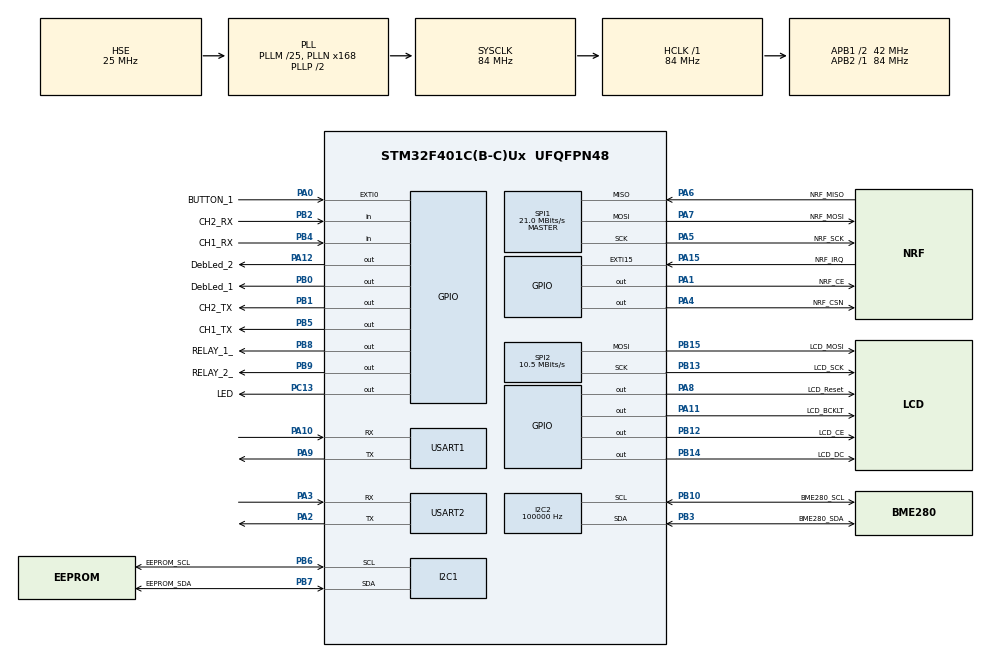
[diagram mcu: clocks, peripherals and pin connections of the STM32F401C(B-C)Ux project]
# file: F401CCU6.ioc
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Dma.Request0=SPI2_TX
Dma.SPI2_TX.0.Direction=DMA_MEMORY_TO_PERIPH
Dma.SPI2_TX.0.FIFOMode=DMA_FIFOMODE_DISABLE
Dma.SPI2_TX.0.Instance=DMA1_Stream4
Dma.SPI2_TX.0.MemDataAlignment=DMA_MDATAALIGN_BYTE
Dma.SPI2_TX.0.MemInc=DMA_MINC_ENABLE
Dma.SPI2_TX.0.Mode=DMA_NORMAL
Dma.SPI2_TX.0.PeriphDataAlignment=DMA_PDATAALIGN_BYTE
Dma.SPI2_TX.0.PeriphInc=DMA_PINC_DISABLE
Dma.SPI2_TX.0.Priority=DMA_PRIORITY_LOW
FREERTOS.CountingSemaphores01=localMsmntSem,5,Static,localMsmntSemControlBlock;txPrintSem,5,Static,nRF_txPrintSemControlBlock;tableSensDataSem,5,Static,tableSensDataSemControlBlock
FREERTOS.Queues01=remoteDataQueue,20,18,1,Static,remoteMsmntQueueBuffer,remoteMsmntQueueControlBlock
FREERTOS.Tasks01=measureTask,24,300,startMeasureTask,As weak,NULL,Static,measureTaskBuffer,measureTaskControlBlock;nRF24Task,24,200,startnRF24Task,As external,NULL,Static,nRF24TaskBuffer,nRF24TaskControlBlock;displayTask,8,200,startDisplayTask,As external,NULL,Static,displayTaskBuffer,displayTaskControlBlock;masterSerialTas,8,400,startMasterSerialTask,As external,NULL,Static,masterSerialTasBuffer,masterSerialTasControlBlock
FREERTOS.Timers01=ownSysTickTimer,ownSysTick,osTimerPeriodic,As weak,NULL,Static,ownSysTickTimerControlBlock
FREERTOS.configUSE_NEWLIB_REENTRANT=1
I2C1.I2C_Mode=I2C_Fast
I2C2.ClockSpeed=100000
I2C2.I2C_Mode=I2C_Fast
Mcu.Family=STM32F4
Mcu.Name=STM32F401C(B-C)Ux
Mcu.Package=UFQFPN48
NVIC.DMA1_Stream4_IRQn=true\:5\:0\:false\:false\:true\:true\:false\:true\:true
NVIC.EXTI0_IRQn=true\:5\:0\:false\:false\:true\:true\:true\:true\:true
NVIC.EXTI15_10_IRQn=true\:5\:0\:false\:false\:true\:true\:true\:true\:true
NVIC.I2C1_ER_IRQn=true\:5\:0\:false\:false\:true\:true\:true\:true\:true
NVIC.I2C1_EV_IRQn=true\:5\:0\:false\:false\:true\:true\:true\:true\:true
NVIC.I2C2_ER_IRQn=true\:5\:0\:false\:false\:true\:true\:true\:true\:true
NVIC.I2C2_EV_IRQn=true\:5\:0\:false\:false\:true\:true\:true\:true\:true
NVIC.PriorityGroup=NVIC_PRIORITYGROUP_4
NVIC.SPI1_IRQn=true\:5\:0\:false\:false\:true\:true\:true\:true\:true
NVIC.SPI2_IRQn=true\:5\:0\:false\:false\:true\:true\:true\:true\:true
NVIC.TIM4_IRQn=true\:15\:0\:false\:false\:true\:false\:false\:true\:true
NVIC.TimeBase=TIM4_IRQn
NVIC.TimeBaseIP=TIM4
NVIC.USART1_IRQn=true\:5\:0\:false\:false\:true\:true\:true\:true\:true
NVIC.USART2_IRQn=true\:5\:0\:false\:false\:true\:true\:true\:true\:true
PA0-WKUP.GPIO_Label=BUTTON_1
PA0-WKUP.GPIO_PuPd=GPIO_PULLUP
PA0-WKUP.Signal=GPXTI0
PA1.GPIO_Label=NRF_CE
PA1.Signal=GPIO_Output
PA10.Mode=Asynchronous
PA10.Signal=USART1_RX
PA11.GPIO_Label=LCD_BCKLT
PA11.Signal=GPIO_Output
PA12.GPIO_Label=DebLed_2
PA12.Signal=GPIO_Output
PA13.Mode=Serial_Wire
PA13.Signal=SYS_JTMS-SWDIO
PA14.Mode=Serial_Wire
PA14.Signal=SYS_JTCK-SWCLK
PA15.GPIO_Label=NRF_IRQ
PA15.GPIO_ModeDefaultEXTI=GPIO_MODE_IT_FALLING
PA15.Signal=GPXTI15
PA2.Mode=Asynchronous
PA2.Signal=USART2_TX
PA3.Mode=Asynchronous
PA3.Signal=USART2_RX
PA4.GPIO_Label=NRF_CSN
PA4.Signal=GPIO_Output
PA5.GPIO_Label=NRF_SCK
PA5.Mode=Full_Duplex_Master
PA5.Signal=SPI1_SCK
PA6.GPIO_Label=NRF_MISO
PA6.Mode=Full_Duplex_Master
PA6.Signal=SPI1_MISO
PA7.GPIO_Label=NRF_MOSI
PA7.Mode=Full_Duplex_Master
PA7.Signal=SPI1_MOSI
PA8.GPIO_Label=LCD_Reset
PA8.Signal=GPIO_Output
PA9.Mode=Asynchronous
PA9.Signal=USART1_TX
PB0.GPIO_Label=DebLed_1
PB0.Signal=GPIO_Output
PB1.GPIO_Label=CH2_TX
PB1.Signal=GPIO_Output
PB10.GPIO_Label=BME280_SCL
PB10.Mode=I2C
PB10.Signal=I2C2_SCL
PB12.GPIO_Label=LCD_CE
PB12.Signal=GPIO_Output
PB13.GPIO_Label=LCD_SCK
PB13.Mode=TX_Only_Simplex_Unidirect_Master
PB13.Signal=SPI2_SCK
PB14.GPIO_Label=LCD_DC
PB14.Signal=GPIO_Output
PB15.GPIO_Label=LCD_MOSI
PB15.Mode=TX_Only_Simplex_Unidirect_Master
PB15.Signal=SPI2_MOSI
PB2.GPIO_Label=CH2_RX
PB2.Signal=GPIO_Input
PB3.GPIO_Label=BME280_SDA
PB3.Mode=I2C
PB3.Signal=I2C2_SDA
PB4.GPIO_Label=CH1_RX
PB4.Signal=GPIO_Input
PB5.GPIO_Label=CH1_TX
PB5.Signal=GPIO_Output
PB6.GPIO_Label=EEPROM_SCL
PB6.Mode=I2C
PB6.Signal=I2C1_SCL
PB7.GPIO_Label=EEPROM_SDA
PB7.Mode=I2C
PB7.Signal=I2C1_SDA
PB8.GPIO_Label=RELAY_1_
PB8.Signal=GPIO_Output
PB9.GPIO_Label=RELAY_2_
PB9.Signal=GPIO_Output
PC13-ANTI_TAMP.GPIO_Label=LED
PC13-ANTI_TAMP.Signal=GPIO_Output
PC14-OSC32_IN.Mode=LSE-External-Oscillator
PC14-OSC32_IN.Signal=RCC_OSC32_IN
PC15-OSC32_OUT.Mode=LSE-External-Oscillator
PC15-OSC32_OUT.Signal=RCC_OSC32_OUT
PH0\ -\ OSC_IN.Mode=HSE-External-Oscillator
PH0\ -\ OSC_IN.Signal=RCC_OSC_IN
PH1\ -\ OSC_OUT.Mode=HSE-External-Oscillator
PH1\ -\ OSC_OUT.Signal=RCC_OSC_OUT
ProjectManager.HeapSize=0x200
ProjectManager.StackSize=0x400
ProjectManager.TargetToolchain=STM32CubeIDE
RCC.48MHZClocksFreq_Value=42000000
RCC.AHBFreq_Value=84000000
RCC.APB1CLKDivider=RCC_HCLK_DIV2
RCC.APB1Freq_Value=42000000
RCC.APB1TimFreq_Value=84000000
RCC.APB2Freq_Value=84000000
RCC.APB2TimFreq_Value=84000000
RCC.CortexFreq_Value=84000000
RCC.HCLKFreq_Value=84000000
RCC.HSE_VALUE=25000000
RCC.HSI_VALUE=16000000
RCC.PLLM=25
RCC.PLLN=168
RCC.PLLSourceVirtual=RCC_PLLSOURCE_HSE
RCC.SYSCLKFreq_VALUE=84000000
RCC.SYSCLKSource=RCC_SYSCLKSOURCE_PLLCLK
RCC.VCOOutputFreq_Value=168000000
SPI1.BaudRatePrescaler=SPI_BAUDRATEPRESCALER_4
SPI1.CalculateBaudRate=21.0 MBits/s
SPI1.Direction=SPI_DIRECTION_2LINES
SPI1.Mode=SPI_MODE_MASTER
SPI1.VirtualType=VM_MASTER
SPI2.BaudRatePrescaler=SPI_BAUDRATEPRESCALER_4
SPI2.CalculateBaudRate=10.5 MBits/s
SPI2.Direction=SPI_DIRECTION_2LINES
SPI2.Mode=SPI_MODE_MASTER
SPI2.VirtualType=VM_MASTER
TIM1.Prescaler=83
TIM2.Prescaler=82
USART1.VirtualMode=VM_ASYNC
USART2.VirtualMode=VM_ASYNC
VP_CRC_VS_CRC.Mode=CRC_Activate
VP_FREERTOS_VS_CMSIS_V2.Mode=CMSIS_V2
VP_SYS_VS_tim4.Mode=TIM4
VP_TIM1_VS_ClockSourceINT.Mode=Internal
VP_TIM2_VS_ClockSourceINT.Mode=Internal
board=custom

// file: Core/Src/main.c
/* USER CODE BEGIN Header */
/**
  ******************************************************************************
  * @file           : main.c
  * @brief          : Main program body
  ******************************************************************************
  * @attention
  *
  * Copyright (c) 2022 STMicroelectronics.
  * All rights reserved.
  *
  * This software is licensed under terms that can be found in the LICENSE file
  * in the root directory of this software component.
  * If no LICENSE file comes with this software, it is provided AS-IS.
  *
  ******************************************************************************
  */
/* USER CODE END Header */
#include "main.h"
#include "cmsis_os.h"

typedef StaticTask_t osStaticThreadDef_t;
typedef StaticQueue_t osStaticMessageQDef_t;
typedef StaticTimer_t osStaticTimerDef_t;
typedef StaticSemaphore_t osStaticSemaphoreDef_t;

CRC_HandleTypeDef hcrc;

I2C_HandleTypeDef hi2c1;
I2C_HandleTypeDef hi2c2;

SPI_HandleTypeDef hspi1;
SPI_HandleTypeDef hspi2;
DMA_HandleTypeDef hdma_spi2_tx;

TIM_HandleTypeDef htim1;
TIM_HandleTypeDef htim2;

UART_HandleTypeDef huart1;
UART_HandleTypeDef huart2;

/* Definitions for measureTask */
osThreadId_t measureTaskHandle;
uint32_t measureTaskBuffer[ 300 ];
osStaticThreadDef_t measureTaskControlBlock;
const osThreadAttr_t measureTask_attributes = {
  .name = "measureTask",
  .cb_mem = &measureTaskControlBlock,
  .cb_size = sizeof(measureTaskControlBlock),
  .stack_mem = &measureTaskBuffer[0],
  .stack_size = sizeof(measureTaskBuffer),
  .priority = (osPriority_t) osPriorityNormal,
};
/* Definitions for nRF24Task */
osThreadId_t nRF24TaskHandle;
uint32_t nRF24TaskBuffer[ 200 ];
osStaticThreadDef_t nRF24TaskControlBlock;
const osThreadAttr_t nRF24Task_attributes = {
  .name = "nRF24Task",
  .cb_mem = &nRF24TaskControlBlock,
  .cb_size = sizeof(nRF24TaskControlBlock),
  .stack_mem = &nRF24TaskBuffer[0],
  .stack_size = sizeof(nRF24TaskBuffer),
  .priority = (osPriority_t) osPriorityNormal,
};
/* Definitions for displayTask */
osThreadId_t displayTaskHandle;
uint32_t displayTaskBuffer[ 200 ];
osStaticThreadDef_t displayTaskControlBlock;
const osThreadAttr_t displayTask_attributes = {
  .name = "displayTask",
  .cb_mem = &displayTaskControlBlock,
  .cb_size = sizeof(displayTaskControlBlock),
  .stack_mem = &displayTaskBuffer[0],
  .stack_size = sizeof(displayTaskBuffer),
  .priority = (osPriority_t) osPriorityLow,
};
/* Definitions for masterSerialTas */
osThreadId_t masterSerialTasHandle;
uint32_t masterSerialTasBuffer[ 400 ];
osStaticThreadDef_t masterSerialTasControlBlock;
const osThreadAttr_t masterSerialTas_attributes = {
  .name = "masterSerialTas",
  .cb_mem = &masterSerialTasControlBlock,
  .cb_size = sizeof(masterSerialTasControlBlock),
  .stack_mem = &masterSerialTasBuffer[0],
  .stack_size = sizeof(masterSerialTasBuffer),
  .priority = (osPriority_t) osPriorityLow,
};
/* Definitions for remoteDataQueue */
osMessageQueueId_t remoteDataQueueHandle;
uint8_t remoteMsmntQueueBuffer[ 20 * 18 ];
osStaticMessageQDef_t remoteMsmntQueueControlBlock;
const osMessageQueueAttr_t remoteDataQueue_attributes = {
  .name = "remoteDataQueue",
  .cb_mem = &remoteMsmntQueueControlBlock,
  .cb_size = sizeof(remoteMsmntQueueControlBlock),
  .mq_mem = &remoteMsmntQueueBuffer,
  .mq_size = sizeof(remoteMsmntQueueBuffer)
};
/* Definitions for ownSysTickTimer */
osTimerId_t ownSysTickTimerHandle;
osStaticTimerDef_t ownSysTickTimerControlBlock;
const osTimerAttr_t ownSysTickTimer_attributes = {
  .name = "ownSysTickTimer",
  .cb_mem = &ownSysTickTimerControlBlock,
  .cb_size = sizeof(ownSysTickTimerControlBlock),
};
/* Definitions for localMsmntSem */
osSemaphoreId_t localMsmntSemHandle;
osStaticSemaphoreDef_t localMsmntSemControlBlock;
const osSemaphoreAttr_t localMsmntSem_attributes = {
  .name = "localMsmntSem",
  .cb_mem = &localMsmntSemControlBlock,
  .cb_size = sizeof(localMsmntSemControlBlock),
};
/* Definitions for txPrintSem */
osSemaphoreId_t txPrintSemHandle;
osStaticSemaphoreDef_t nRF_txPrintSemControlBlock;
const osSemaphoreAttr_t txPrintSem_attributes = {
  .name = "txPrintSem",
  .cb_mem = &nRF_txPrintSemControlBlock,
  .cb_size = sizeof(nRF_txPrintSemControlBlock),
};
/* Definitions for tableSensDataSem */
osSemaphoreId_t tableSensDataSemHandle;
osStaticSemaphoreDef_t tableSensDataSemControlBlock;
const osSemaphoreAttr_t tableSensDataSem_attributes = {
  .name = "tableSensDataSem",
  .cb_mem = &tableSensDataSemControlBlock,
  .cb_size = sizeof(tableSensDataSemControlBlock),
};

void SystemClock_Config(void);
static void MX_GPIO_Init(void);
static void MX_DMA_Init(void);
static void MX_CRC_Init(void);
static void MX_I2C1_Init(void);
static void MX_I2C2_Init(void);
static void MX_SPI1_Init(void);
static void MX_SPI2_Init(void);
static void MX_USART1_UART_Init(void);
static void MX_TIM1_Init(void);
static void MX_TIM2_Init(void);
static void MX_USART2_UART_Init(void);
void startMeasureTask(void *argument);
extern void startnRF24Task(void *argument);
extern void startDisplayTask(void *argument);
extern void startMasterSerialTask(void *argument);
void ownSysTick(void *argument);

int main(void)
{

  /* MCU Configuration--------------------------------------------------------*/

  /* Reset of all peripherals, Initializes the Flash interface and the Systick. */
  HAL_Init();

  /* Configure the system clock */
  SystemClock_Config();

  /* Initialize all configured peripherals */
  MX_GPIO_Init();
  MX_DMA_Init();
  MX_CRC_Init();
  MX_I2C1_Init();
  MX_I2C2_Init();
  MX_SPI1_Init();
  MX_SPI2_Init();
  MX_USART1_UART_Init();
  MX_TIM1_Init();
  MX_TIM2_Init();
  MX_USART2_UART_Init();

  /* Init scheduler */
  osKernelInitialize();

  /* Create the semaphores(s) */
  /* creation of localMsmntSem */
  localMsmntSemHandle = osSemaphoreNew(5, 5, &localMsmntSem_attributes);

  /* creation of txPrintSem */
  txPrintSemHandle = osSemaphoreNew(5, 5, &txPrintSem_attributes);

  /* creation of tableSensDataSem */
  tableSensDataSemHandle = osSemaphoreNew(5, 5, &tableSensDataSem_attributes);

  /* Create the timer(s) */
  /* creation of ownSysTickTimer */
  ownSysTickTimerHandle = osTimerNew(ownSysTick, osTimerPeriodic, NULL, &ownSysTickTimer_attributes);

  /* Create the queue(s) */
  /* creation of remoteDataQueue */
  remoteDataQueueHandle = osMessageQueueNew (20, 18, &remoteDataQueue_attributes);

  /* Create the thread(s) */
  /* creation of measureTask */
  measureTaskHandle = osThreadNew(startMeasureTask, NULL, &measureTask_attributes);

  /* creation of nRF24Task */
  nRF24TaskHandle = osThreadNew(startnRF24Task, NULL, &nRF24Task_attributes);

  /* creation of displayTask */
  displayTaskHandle = osThreadNew(startDisplayTask, NULL, &displayTask_attributes);

  /* creation of masterSerialTas */
  masterSerialTasHandle = osThreadNew(startMasterSerialTask, NULL, &masterSerialTas_attributes);

  /* Start scheduler */
  osKernelStart();

  /* We should never get here as control is now taken by the scheduler */
  /* Infinite loop */
  while (1)
  {

  }
}

void SystemClock_Config(void)
{
  RCC_OscInitTypeDef RCC_OscInitStruct = {0};
  RCC_ClkInitTypeDef RCC_ClkInitStruct = {0};

  /** Configure the main internal regulator output voltage
  */
  __HAL_RCC_PWR_CLK_ENABLE();
  __HAL_PWR_VOLTAGESCALING_CONFIG(PWR_REGULATOR_VOLTAGE_SCALE2);

  /** Initializes the RCC Oscillators according to the specified parameters
  * in the RCC_OscInitTypeDef structure.
  */
  RCC_OscInitStruct.OscillatorType = RCC_OSCILLATORTYPE_HSE;
  RCC_OscInitStruct.HSEState = RCC_HSE_ON;
  RCC_OscInitStruct.PLL.PLLState = RCC_PLL_ON;
  RCC_OscInitStruct.PLL.PLLSource = RCC_PLLSOURCE_HSE;
  RCC_OscInitStruct.PLL.PLLM = 25;
  RCC_OscInitStruct.PLL.PLLN = 168;
  RCC_OscInitStruct.PLL.PLLP = RCC_PLLP_DIV2;
  RCC_OscInitStruct.PLL.PLLQ = 4;
  if (HAL_RCC_OscConfig(&RCC_OscInitStruct) != HAL_OK)
  {
    Error_Handler();
  }

  /** Initializes the CPU, AHB and APB buses clocks
  */
  RCC_ClkInitStruct.ClockType = RCC_CLOCKTYPE_HCLK|RCC_CLOCKTYPE_SYSCLK
                              |RCC_CLOCKTYPE_PCLK1|RCC_CLOCKTYPE_PCLK2;
  RCC_ClkInitStruct.SYSCLKSource = RCC_SYSCLKSOURCE_PLLCLK;
  RCC_ClkInitStruct.AHBCLKDivider = RCC_SYSCLK_DIV1;
  RCC_ClkInitStruct.APB1CLKDivider = RCC_HCLK_DIV2;
  RCC_ClkInitStruct.APB2CLKDivider = RCC_HCLK_DIV1;

  if (HAL_RCC_ClockConfig(&RCC_ClkInitStruct, FLASH_LATENCY_2) != HAL_OK)
  {
    Error_Handler();
  }
}

static void MX_CRC_Init(void)
{

  hcrc.Instance = CRC;
  if (HAL_CRC_Init(&hcrc) != HAL_OK)
  {
    Error_Handler();
  }

}

static void MX_I2C1_Init(void)
{

  hi2c1.Instance = I2C1;
  hi2c1.Init.ClockSpeed = 400000;
  hi2c1.Init.DutyCycle = I2C_DUTYCYCLE_2;
  hi2c1.Init.OwnAddress1 = 0;
  hi2c1.Init.AddressingMode = I2C_ADDRESSINGMODE_7BIT;
  hi2c1.Init.DualAddressMode = I2C_DUALADDRESS_DISABLE;
  hi2c1.Init.OwnAddress2 = 0;
  hi2c1.Init.GeneralCallMode = I2C_GENERALCALL_DISABLE;
  hi2c1.Init.NoStretchMode = I2C_NOSTRETCH_DISABLE;
  if (HAL_I2C_Init(&hi2c1) != HAL_OK)
  {
    Error_Handler();
  }

}

static void MX_I2C2_Init(void)
{

  hi2c2.Instance = I2C2;
  hi2c2.Init.ClockSpeed = 100000;
  hi2c2.Init.DutyCycle = I2C_DUTYCYCLE_2;
  hi2c2.Init.OwnAddress1 = 0;
  hi2c2.Init.AddressingMode = I2C_ADDRESSINGMODE_7BIT;
  hi2c2.Init.DualAddressMode = I2C_DUALADDRESS_DISABLE;
  hi2c2.Init.OwnAddress2 = 0;
  hi2c2.Init.GeneralCallMode = I2C_GENERALCALL_DISABLE;
  hi2c2.Init.NoStretchMode = I2C_NOSTRETCH_DISABLE;
  if (HAL_I2C_Init(&hi2c2) != HAL_OK)
  {
    Error_Handler();
  }

}

static void MX_SPI1_Init(void)
{

  /* SPI1 parameter configuration*/
  hspi1.Instance = SPI1;
  hspi1.Init.Mode = SPI_MODE_MASTER;
  hspi1.Init.Direction = SPI_DIRECTION_2LINES;
  hspi1.Init.DataSize = SPI_DATASIZE_8BIT;
  hspi1.Init.CLKPolarity = SPI_POLARITY_LOW;
  hspi1.Init.CLKPhase = SPI_PHASE_1EDGE;
  hspi1.Init.NSS = SPI_NSS_SOFT;
  hspi1.Init.BaudRatePrescaler = SPI_BAUDRATEPRESCALER_4;
  hspi1.Init.FirstBit = SPI_FIRSTBIT_MSB;
  hspi1.Init.TIMode = SPI_TIMODE_DISABLE;
  hspi1.Init.CRCCalculation = SPI_CRCCALCULATION_DISABLE;
  hspi1.Init.CRCPolynomial = 10;
  if (HAL_SPI_Init(&hspi1) != HAL_OK)
  {
    Error_Handler();
  }
  /* USER CODE BEGIN SPI1_Init 2 */
  /* SPI1 parameter configuration*/
  /* USER CODE END SPI1_Init 2 */

}

static void MX_SPI2_Init(void)
{

  /* SPI2 parameter configuration*/
  hspi2.Instance = SPI2;
  hspi2.Init.Mode = SPI_MODE_MASTER;
  hspi2.Init.Direction = SPI_DIRECTION_2LINES;
  hspi2.Init.DataSize = SPI_DATASIZE_8BIT;
  hspi2.Init.CLKPolarity = SPI_POLARITY_LOW;
  hspi2.Init.CLKPhase = SPI_PHASE_1EDGE;
  hspi2.Init.NSS = SPI_NSS_SOFT;
  hspi2.Init.BaudRatePrescaler = SPI_BAUDRATEPRESCALER_4;
  hspi2.Init.FirstBit = SPI_FIRSTBIT_MSB;
  hspi2.Init.TIMode = SPI_TIMODE_DISABLE;
  hspi2.Init.CRCCalculation = SPI_CRCCALCULATION_DISABLE;
  hspi2.Init.CRCPolynomial = 10;
  if (HAL_SPI_Init(&hspi2) != HAL_OK)
  {
    Error_Handler();
  }

}

static void MX_TIM1_Init(void)
{

  TIM_ClockConfigTypeDef sClockSourceConfig = {0};
  TIM_MasterConfigTypeDef sMasterConfig = {0};

  htim1.Instance = TIM1;
  htim1.Init.Prescaler = 83;
  htim1.Init.CounterMode = TIM_COUNTERMODE_UP;
  htim1.Init.Period = 65535;
  htim1.Init.ClockDivision = TIM_CLOCKDIVISION_DIV1;
  htim1.Init.RepetitionCounter = 0;
  htim1.Init.AutoReloadPreload = TIM_AUTORELOAD_PRELOAD_DISABLE;
  if (HAL_TIM_Base_Init(&htim1) != HAL_OK)
  {
    Error_Handler();
  }
  sClockSourceConfig.ClockSource = TIM_CLOCKSOURCE_INTERNAL;
  if (HAL_TIM_ConfigClockSource(&htim1, &sClockSourceConfig) != HAL_OK)
  {
    Error_Handler();
  }
  sMasterConfig.MasterOutputTrigger = TIM_TRGO_RESET;
  sMasterConfig.MasterSlaveMode = TIM_MASTERSLAVEMODE_DISABLE;
  if (HAL_TIMEx_MasterConfigSynchronization(&htim1, &sMasterConfig) != HAL_OK)
  {
    Error_Handler();
  }

}

static void MX_TIM2_Init(void)
{

  TIM_ClockConfigTypeDef sClockSourceConfig = {0};
  TIM_MasterConfigTypeDef sMasterConfig = {0};

  htim2.Instance = TIM2;
  htim2.Init.Prescaler = 82;
  htim2.Init.CounterMode = TIM_COUNTERMODE_UP;
  htim2.Init.Period = 4294967295;
  htim2.Init.ClockDivision = TIM_CLOCKDIVISION_DIV1;
  htim2.Init.AutoReloadPreload = TIM_AUTORELOAD_PRELOAD_DISABLE;
  if (HAL_TIM_Base_Init(&htim2) != HAL_OK)
  {
    Error_Handler();
  }
  sClockSourceConfig.ClockSource = TIM_CLOCKSOURCE_INTERNAL;
  if (HAL_TIM_ConfigClockSource(&htim2, &sClockSourceConfig) != HAL_OK)
  {
    Error_Handler();
  }
  sMasterConfig.MasterOutputTrigger = TIM_TRGO_RESET;
  sMasterConfig.MasterSlaveMode = TIM_MASTERSLAVEMODE_DISABLE;
  if (HAL_TIMEx_MasterConfigSynchronization(&htim2, &sMasterConfig) != HAL_OK)
  {
    Error_Handler();
  }

}

static void MX_USART1_UART_Init(void)
{

  huart1.Instance = USART1;
  huart1.Init.BaudRate = 115200;
  huart1.Init.WordLength = UART_WORDLENGTH_8B;
  huart1.Init.StopBits = UART_STOPBITS_1;
  huart1.Init.Parity = UART_PARITY_NONE;
  huart1.Init.Mode = UART_MODE_TX_RX;
  huart1.Init.HwFlowCtl = UART_HWCONTROL_NONE;
  huart1.Init.OverSampling = UART_OVERSAMPLING_16;
  if (HAL_UART_Init(&huart1) != HAL_OK)
  {
    Error_Handler();
  }

}

static void MX_USART2_UART_Init(void)
{

  huart2.Instance = USART2;
  huart2.Init.BaudRate = 115200;
  huart2.Init.WordLength = UART_WORDLENGTH_8B;
  huart2.Init.StopBits = UART_STOPBITS_1;
  huart2.Init.Parity = UART_PARITY_NONE;
  huart2.Init.Mode = UART_MODE_TX_RX;
  huart2.Init.HwFlowCtl = UART_HWCONTROL_NONE;
  huart2.Init.OverSampling = UART_OVERSAMPLING_16;
  if (HAL_UART_Init(&huart2) != HAL_OK)
  {
    Error_Handler();
  }

}

static void MX_DMA_Init(void)
{

  /* DMA controller clock enable */
  __HAL_RCC_DMA1_CLK_ENABLE();

  /* DMA interrupt init */
  /* DMA1_Stream4_IRQn interrupt configuration */
  HAL_NVIC_SetPriority(DMA1_Stream4_IRQn, 5, 0);
  HAL_NVIC_EnableIRQ(DMA1_Stream4_IRQn);

}

static void MX_GPIO_Init(void)
{
  GPIO_InitTypeDef GPIO_InitStruct = {0};

  /* GPIO Ports Clock Enable */
  __HAL_RCC_GPIOC_CLK_ENABLE();
  __HAL_RCC_GPIOH_CLK_ENABLE();
  __HAL_RCC_GPIOA_CLK_ENABLE();
  __HAL_RCC_GPIOB_CLK_ENABLE();

  /*Configure GPIO pin Output Level */
  HAL_GPIO_WritePin(LED_GPIO_Port, LED_Pin, GPIO_PIN_RESET);

  /*Configure GPIO pin Output Level */
  HAL_GPIO_WritePin(GPIOA, NRF_CE_Pin|NRF_CSN_Pin|LCD_Reset_Pin|LCD_BCKLT_Pin
                          |DebLed_2_Pin, GPIO_PIN_RESET);

  /*Configure GPIO pin Output Level */
  HAL_GPIO_WritePin(GPIOB, DebLed_1_Pin|CH2_TX_Pin|LCD_CE_Pin|LCD_DC_Pin
                          |CH1_TX_Pin|RELAY_1__Pin|RELAY_2__Pin, GPIO_PIN_RESET);

  /*Configure GPIO pin : LED_Pin */
  GPIO_InitStruct.Pin = LED_Pin;
  GPIO_InitStruct.Mode = GPIO_MODE_OUTPUT_PP;
  GPIO_InitStruct.Pull = GPIO_NOPULL;
  GPIO_InitStruct.Speed = GPIO_SPEED_FREQ_LOW;
  HAL_GPIO_Init(LED_GPIO_Port, &GPIO_InitStruct);

  /*Configure GPIO pin : BUTTON_1_Pin */
  GPIO_InitStruct.Pin = BUTTON_1_Pin;
  GPIO_InitStruct.Mode = GPIO_MODE_IT_RISING;
  GPIO_InitStruct.Pull = GPIO_PULLUP;
  HAL_GPIO_Init(BUTTON_1_GPIO_Port, &GPIO_InitStruct);

  /*Configure GPIO pins : NRF_CE_Pin NRF_CSN_Pin LCD_Reset_Pin LCD_BCKLT_Pin
                           DebLed_2_Pin */
  GPIO_InitStruct.Pin = NRF_CE_Pin|NRF_CSN_Pin|LCD_Reset_Pin|LCD_BCKLT_Pin
                          |DebLed_2_Pin;
  GPIO_InitStruct.Mode = GPIO_MODE_OUTPUT_PP;
  GPIO_InitStruct.Pull = GPIO_NOPULL;
  GPIO_InitStruct.Speed = GPIO_SPEED_FREQ_LOW;
  HAL_GPIO_Init(GPIOA, &GPIO_InitStruct);

  /*Configure GPIO pins : DebLed_1_Pin CH2_TX_Pin LCD_CE_Pin LCD_DC_Pin
                           CH1_TX_Pin RELAY_1__Pin RELAY_2__Pin */
  GPIO_InitStruct.Pin = DebLed_1_Pin|CH2_TX_Pin|LCD_CE_Pin|LCD_DC_Pin
                          |CH1_TX_Pin|RELAY_1__Pin|RELAY_2__Pin;
  GPIO_InitStruct.Mode = GPIO_MODE_OUTPUT_PP;
  GPIO_InitStruct.Pull = GPIO_NOPULL;
  GPIO_InitStruct.Speed = GPIO_SPEED_FREQ_LOW;
  HAL_GPIO_Init(GPIOB, &GPIO_InitStruct);

  /*Configure GPIO pins : CH2_RX_Pin CH1_RX_Pin */
  GPIO_InitStruct.Pin = CH2_RX_Pin|CH1_RX_Pin;
  GPIO_InitStruct.Mode = GPIO_MODE_INPUT;
  GPIO_InitStruct.Pull = GPIO_NOPULL;
  HAL_GPIO_Init(GPIOB, &GPIO_InitStruct);

  /*Configure GPIO pin : NRF_IRQ_Pin */
  GPIO_InitStruct.Pin = NRF_IRQ_Pin;
  GPIO_InitStruct.Mode = GPIO_MODE_IT_FALLING;
  GPIO_InitStruct.Pull = GPIO_NOPULL;
  HAL_GPIO_Init(NRF_IRQ_GPIO_Port, &GPIO_InitStruct);

  /* EXTI interrupt init*/
  HAL_NVIC_SetPriority(EXTI0_IRQn, 5, 0);
  HAL_NVIC_EnableIRQ(EXTI0_IRQn);

  HAL_NVIC_SetPriority(EXTI15_10_IRQn, 5, 0);
  HAL_NVIC_EnableIRQ(EXTI15_10_IRQn);

}

__weak void startMeasureTask(void *argument)
{
  for(;;)
  {
    osDelay(1);
  }
}

/* ownSysTick function */
__weak void ownSysTick(void *argument)
{
}

void HAL_TIM_PeriodElapsedCallback(TIM_HandleTypeDef *htim)
{
  if (htim->Instance == TIM4) {
    HAL_IncTick();
  }
}

void Error_Handler(void)
{
  __disable_irq();
  while (1)
  {
  }
}
